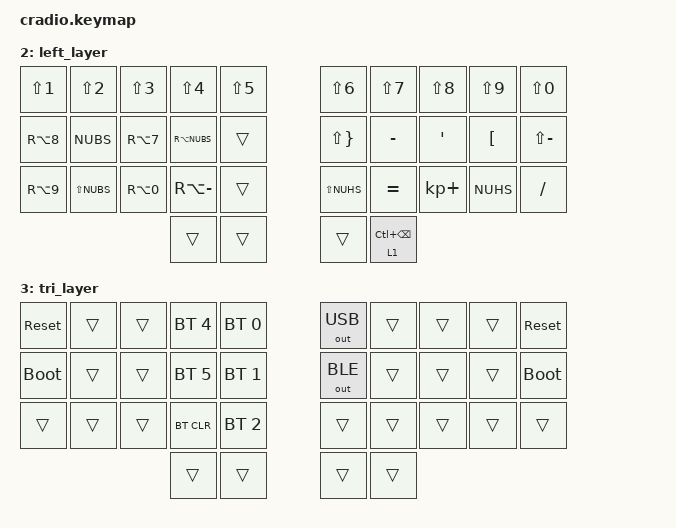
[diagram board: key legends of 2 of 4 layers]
// Copyright (c) 2022 The ZMK Contributors
// SPDX-License-Identifier: MIT

#include <behaviors.dtsi>
#include <dt-bindings/zmk/keys.h>
#include <dt-bindings/zmk/bt.h>
#include <dt-bindings/zmk/outputs.h>

// Home row mods macro
#define HRML(k1,k2,k3) &ht LGUI k1  &ht LALT k2  &ht LCTRL k3
#define HRMR(k1,k2,k3) &ht RCTRL k1  &ht RALT k2  &ht RGUI k3

// Weitere macros
#define XCV(k1,k2,k3) &ht RC(X) k1  &ht RC(C) k2  &ht RC(V) k3
#define CT(k1,k2,k3,k4,k5) &ht RC(N1) k1    &ht RC(N2) k2 &ht RC(N3) k3   &ht RC(N4) k4   &ht RC(N5) k5
#define UDO(k1) &ht RC(Y) k1

/ {
    combos {
        compatible = "zmk,combos";
        combo_esc {
            timeout-ms = <50>;
            key-positions = <0 1>;
            bindings = <&kp ESC>;
        };
        combo_tab {
            timeout-ms = <50>;
            key-positions = <10 11>;
            bindings = <&kp TAB>;
        };
        combo_capslock {
            timeout-ms = <50>;
            key-positions = <20 21>;
            bindings = <&kp CAPS>;
        };   
        combo_del {
            timeout-ms = <50>;
            key-positions = <26 27>;
            bindings = <&kp DEL>;
        };
    };
};

/ {
    behaviors {
        ht: hold_tap {
            compatible = "zmk,behavior-hold-tap";
            #binding-cells = <2>;
            flavor = "tap-preferred";
            tapping-term-ms = <220>;
            quick-tap-ms = <150>;
            require-prior-idle-ms = <100>;
            bindings = <&kp>, <&kp>;
        };
    };

    conditional_layers {
        compatible = "zmk,conditional-layers";
        tri_layer {
            if-layers = <1 2>;
            then-layer = <3>;
        };
    };

    keymap {
        compatible = "zmk,keymap";
        default_layer {
            bindings = <
        //╭──────────┬──────────┬──────────┬──────────┬──────────╮   ╭──────────┬──────────┬──────────┬──────────┬──────────╮
            &kp Q      &kp W      &kp E      &kp R      &kp T          UDO(Y)       &kp U      &kp I      &kp O      &kp P
        //├──────────┼──────────┼──────────┼──────────┼──────────┤   ├──────────┼──────────┼──────────┼──────────┼──────────┤
            &kp A      HRML( S,         D,         F)     &kp G          &kp H      HRMR(J,        K,         L)    &kp SEMI
        //├──────────┼──────────┼──────────┼──────────┼──────────┤   ├──────────┼──────────┼──────────┼──────────┼──────────┤
            &mt LSHFT Z   XCV( X,    C,       V)      &kp B          &kp N      &kp M      &kp COMMA  &kp DOT    &mt RSHFT FSLH
        //╰──────────┴──────────┴──────────┼──────────┼──────────┤   ├──────────┼──────────┼──────────┴──────────┴──────────╯
                                            &mo 2   &mt LSHFT ENTER     &kp SPACE  &lt 1 BSPC
        //                                 ╰──────────┴──────────╯   ╰──────────┴──────────╯
            >;
        };

        right_layer {
            bindings = <
        //╭──────────┬──────────┬──────────┬──────────┬──────────╮   ╭──────────┬──────────┬──────────┬──────────┬──────────╮
            CT( N1,       N2,       N3,       N4,         N5)        &kp N6      &kp N7    &kp N8     &kp N9     &kp N0
        //├──────────┼──────────┼──────────┼──────────┼──────────┤   ├──────────┼──────────┼──────────┼──────────┼──────────┤
            &kp F11    &kp F12    &kp PG_UP  &kp PG_DN  &kp HOME       &kp LARW   &kp DARW   &kp UARW   &kp RARW   &kp END
        //├──────────┼──────────┼──────────┼──────────┼──────────┤   ├──────────┼──────────┼──────────┼──────────┼──────────┤
            &kp F1     &kp F2      &kp F3    &kp F4     &kp F5         &kp F6      &kp F7    &kp F8     &kp F9     &kp F10
        //╰──────────┴──────────┴──────────┼──────────┼──────────┤   ├──────────┼──────────┼──────────┴──────────┴──────────╯
                                             &trans     &kp ESC        &trans     &trans
        //                                 ╰──────────┴──────────╯   ╰──────────┴──────────╯
            >;
        };

        left_layer {
            bindings = <
        //╭──────────┬──────────┬──────────┬──────────┬──────────╮   ╭──────────┬──────────┬──────────┬──────────┬──────────╮
            &kp LS(N1) &kp LS(N2) &kp LS(N3) &kp LS(N4) &kp LS(N5)    &kp LS(N6) &kp LS(N7)  &kp LS(N8) &kp LS(N9) &kp LS(N0)
        //├──────────┼──────────┼──────────┼──────────┼──────────┤   ├──────────┼──────────┼──────────┼──────────┼──────────┤
            &kp RA(N8)  &kp NUBS   &kp RA(N7) &kp RA(NUBS) &trans     &kp LS(RBRC) &kp MINUS &kp SQT   &kp LBKT   &kp LS(MINUS)
        //├──────────┼──────────┼──────────┼──────────┼──────────┤   ├──────────┼──────────┼──────────┼──────────┼──────────┤
            &kp RA(N9)  &kp LS(NUBS) &kp RA(N0) &kp RA(MINUS) &trans  &kp LS(NUHS) &kp EQUAL &kp KP_PLUS  &kp NUHS  &kp SLASH
        //╰──────────┴──────────┴──────────┼──────────┼──────────┤   ├──────────┼──────────┼──────────┴──────────┴──────────╯
                                             &trans     &trans         &trans     &lt 1 LC(BSPC)
        //                                 ╰──────────┴──────────╯   ╰──────────┴──────────╯
            >;
        };

        tri_layer {
            bindings = <
        //╭──────────┬──────────┬──────────┬──────────┬──────────╮   ╭──────────┬──────────┬──────────┬──────────┬──────────╮
           &sys_reset  &trans     &trans   &bt BT_SEL 4 &bt BT_SEL 0  &out OUT_USB  &trans     &trans     &trans    &sys_reset
        //├──────────┼──────────┼──────────┼──────────┼──────────┤   ├──────────┼──────────┼──────────┼──────────┼──────────┤
          &bootloader  &trans     &trans   &bt BT_SEL 5 &bt BT_SEL 1  &out OUT_BLE  &trans     &trans     &trans    &bootloader
        //├──────────┼──────────┼──────────┼──────────┼──────────┤   ├──────────┼──────────┼──────────┼──────────┼──────────┤
            &trans     &trans     &trans   &bt BT_CLR &bt BT_SEL 2    &trans     &trans     &trans     &trans     &trans
        //╰──────────┴──────────┴──────────┼──────────┼──────────┤   ├──────────┼──────────┼──────────┴──────────┴──────────╯
                                             &trans     &trans         &trans     &trans
        //                                 ╰──────────┴──────────╯   ╰──────────┴──────────╯
            >;
        };
    };
};
